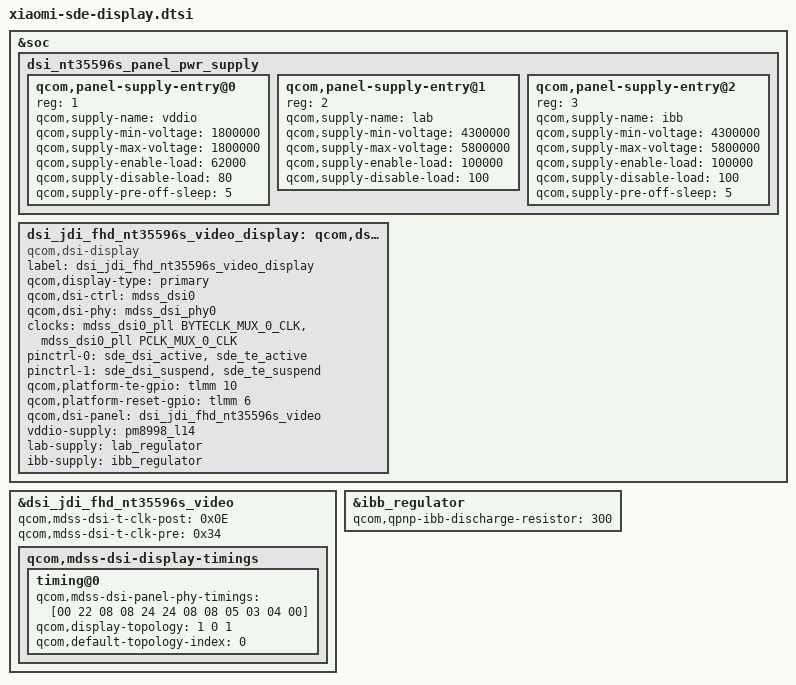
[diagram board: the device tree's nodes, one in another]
/* Copyright (c) 2016-2017, The Linux Foundation. All rights reserved.
 * Copyright (C) 2019 XiaoMi, Inc.
 *
 * This program is free software; you can redistribute it and/or modify
 * it under the terms of the GNU General Public License version 2 and
 * only version 2 as published by the Free Software Foundation.
 *
 * This program is distributed in the hope that it will be useful,
 * but WITHOUT ANY WARRANTY; without even the implied warranty of
 * MERCHANTABILITY or FITNESS FOR A PARTICULAR PURPOSE.  See the
 * GNU General Public License for more details.
 */

#include "dsi-panel-jdi-fhd-nt35596s-video.dtsi"

&soc {
	dsi_nt35596s_panel_pwr_supply: dsi_nt35596s_panel_pwr_supply {
		#address-cells = <1>;
		#size-cells = <0>;

		qcom,panel-supply-entry@0 {
			reg = <1>;
			qcom,supply-name = "vddio";
			qcom,supply-min-voltage = <1800000>;
			qcom,supply-max-voltage = <1800000>;
			qcom,supply-enable-load = <62000>;
			qcom,supply-disable-load = <80>;
			qcom,supply-pre-off-sleep = <5>;
		};

		qcom,panel-supply-entry@1 {
			reg = <2>;
			qcom,supply-name = "lab";
			qcom,supply-min-voltage = <4300000>;
			qcom,supply-max-voltage = <5800000>;
			qcom,supply-enable-load = <100000>;
			qcom,supply-disable-load = <100>;
		};

		qcom,panel-supply-entry@2 {
			reg = <3>;
			qcom,supply-name = "ibb";
			qcom,supply-min-voltage = <4300000>;
			qcom,supply-max-voltage = <5800000>;
			qcom,supply-enable-load = <100000>;
			qcom,supply-disable-load = <100>;
			qcom,supply-pre-off-sleep = <5>;
		};
	};


	dsi_jdi_fhd_nt35596s_video_display: qcom,dsi-display@18 {
		compatible = "qcom,dsi-display";
		label = "dsi_jdi_fhd_nt35596s_video_display";
		qcom,display-type = "primary";
		qcom,dsi-ctrl = <&mdss_dsi0>;
		qcom,dsi-phy = <&mdss_dsi_phy0>;
		clocks = <&mdss_dsi0_pll BYTECLK_MUX_0_CLK>,
			<&mdss_dsi0_pll PCLK_MUX_0_CLK>;
		clock-names = "mux_byte_clk", "mux_pixel_clk";
		pinctrl-names = "panel_active", "panel_suspend";
		pinctrl-0 = <&sde_dsi_active &sde_te_active>;
		pinctrl-1 = <&sde_dsi_suspend &sde_te_suspend>;
		qcom,platform-te-gpio = <&tlmm 10 0>;
		qcom,platform-reset-gpio = <&tlmm 6 0>;
		qcom,dsi-panel = <&dsi_jdi_fhd_nt35596s_video>;
		vddio-supply = <&pm8998_l14>;
		lab-supply = <&lab_regulator>;
		ibb-supply = <&ibb_regulator>;
	};
};

&dsi_jdi_fhd_nt35596s_video {
	qcom,mdss-dsi-t-clk-post = <0x0E>;
	qcom,mdss-dsi-t-clk-pre = <0x34>;
	qcom,mdss-dsi-display-timings {
		timing@0{
			qcom,mdss-dsi-panel-phy-timings = [00 22 08 08 24 24 08 08 05 03 04 00];
			qcom,display-topology = <1 0 1>;
			qcom,default-topology-index = <0>;
		};
	};
};

&ibb_regulator {
	qcom,qpnp-ibb-discharge-resistor = <300>;
};
